# nrf52820 register map
Vendor: Nordic Semiconductor; Series: nrf52; File version: 1
CPU: CM4 r0p1, little endian, MPU, no FPU, 3 interrupt priority bits
Registers are 32-bit, read-write, reset 0x0 unless marked. A register's access mark holds for its fields unless they carry their own. Offsets are from the block's base; [hi:lo] are bit positions; {n}, {i} and the like mark numbered series; 'fields as' and 'values as' point back to an identical list.

## RTC0 — Real time counter 0
Base 0x4000B000
Same registers: RTC1 0x40011000
0x00 TASKS_START wo — Start RTC COUNTER
  [0] TASKS_START
    1=Trigger task
0x04 TASKS_STOP wo — Stop RTC COUNTER
  [0] TASKS_STOP
    1=Trigger task
0x08 TASKS_CLEAR wo — Clear RTC COUNTER
  [0] TASKS_CLEAR
    1=Trigger task
0x0C TASKS_TRIGOVRFLW wo — Set COUNTER to 0xFFFFF0
  [0] TASKS_TRIGOVRFLW
    1=Trigger task
0x100 EVENTS_TICK — Event on COUNTER increment
  [0] EVENTS_TICK
    0=NotGenerated (Event not generated); 1=Generated (Event generated)
0x104 EVENTS_OVRFLW — Event on COUNTER overflow
  [0] EVENTS_OVRFLW
    values as EVENTS_TICK.EVENTS_TICK
{0x140+4i} EVENTS_COMPARE[{i}] (i=0..3) — Description collection: Compare event on CC[n] match
  [0] EVENTS_COMPARE — Compare event on CC[n] match
    values as EVENTS_TICK.EVENTS_TICK
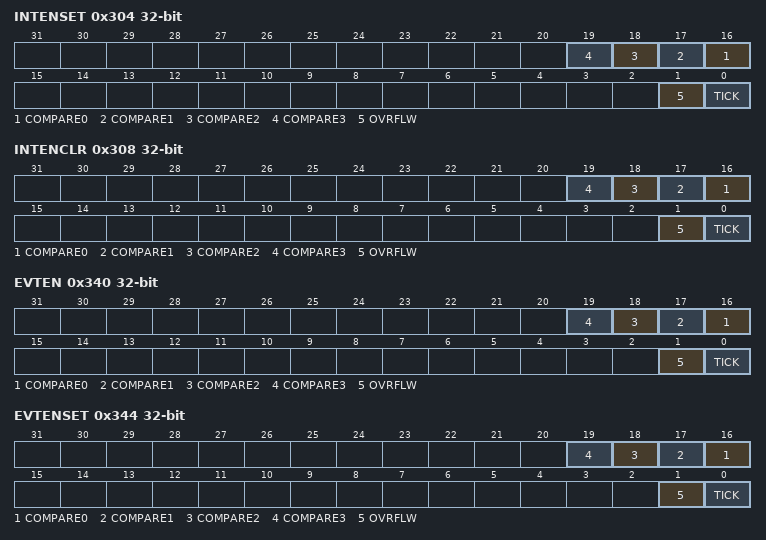
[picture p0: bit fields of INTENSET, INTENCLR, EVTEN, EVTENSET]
0x304 INTENSET — Enable interrupt
  [all] fields
    on read: 0=Disabled (Read: Disabled); 1=Enabled (Read: Enabled) | on write: 1=Set (Enable)
  [n+16] COMPARE{n} (n=0..3) — Write '1' to enable interrupt for event COMPARE[{n}]
  [1] OVRFLW — Write '1' to enable interrupt for event OVRFLW
  [0] TICK — Write '1' to enable interrupt for event TICK
0x308 INTENCLR — Disable interrupt
  [all] fields
    on read: 0=Disabled (Read: Disabled); 1=Enabled (Read: Enabled) | on write: 1=Clear (Disable)
  [n+16] COMPARE{n} (n=0..3) — Write '1' to disable interrupt for event COMPARE[{n}]
  [1] OVRFLW — Write '1' to disable interrupt for event OVRFLW
  [0] TICK — Write '1' to disable interrupt for event TICK
0x340 EVTEN — Enable or disable event routing
  [all] fields
    0=Disabled; 1=Enabled (Disable)
  [n+16] COMPARE{n} (n=0..3) — Enable or disable event routing for event COMPARE[{n}]
  [1] OVRFLW — Enable or disable event routing for event OVRFLW
  [0] TICK — Enable or disable event routing for event TICK
0x344 EVTENSET — Enable event routing
  [all] fields
    values as the fields of INTENSET
  [n+16] COMPARE{n} (n=0..3) — Write '1' to enable event routing for event COMPARE[{n}]
  [1] OVRFLW — Write '1' to enable event routing for event OVRFLW
  [0] TICK — Write '1' to enable event routing for event TICK
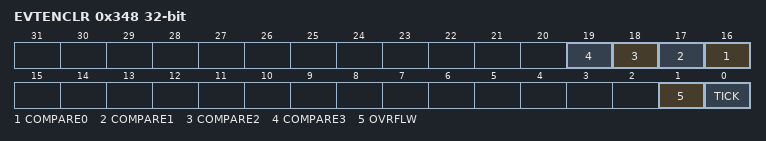
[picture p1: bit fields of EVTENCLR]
0x348 EVTENCLR — Disable event routing
  [all] fields
    values as the fields of INTENCLR
  [n+16] COMPARE{n} (n=0..3) — Write '1' to disable event routing for event COMPARE[{n}]
  [1] OVRFLW — Write '1' to disable event routing for event OVRFLW
  [0] TICK — Write '1' to disable event routing for event TICK
0x504 COUNTER ro — Current COUNTER value
  [23:0] COUNTER — Counter value
0x508 PRESCALER — 12 bit prescaler for COUNTER frequency (32768/(PRESCALER+1)). Must be written when RTC is stopped.
  [11:0] PRESCALER — Prescaler value
{0x540+4i} CC[{i}] (i=0..3) — Description collection: Compare register n
  [23:0] COMPARE — Compare value

## TEMP — Temperature Sensor
Base 0x4000C000
0x00 TASKS_START wo — Start temperature measurement
  [0] TASKS_START
    1=Trigger task
0x04 TASKS_STOP wo — Stop temperature measurement
  [0] TASKS_STOP
    1=Trigger task
0x100 EVENTS_DATARDY — Temperature measurement complete, data ready
  [0] EVENTS_DATARDY
    0=NotGenerated (Event not generated); 1=Generated (Event generated)
0x304 INTENSET — Enable interrupt
  [0] DATARDY — Write '1' to enable interrupt for event DATARDY
    on read: 0=Disabled (Read: Disabled); 1=Enabled (Read: Enabled) | on write: 1=Set (Enable)
0x308 INTENCLR — Disable interrupt
  [0] DATARDY — Write '1' to disable interrupt for event DATARDY
    on read: 0=Disabled (Read: Disabled); 1=Enabled (Read: Enabled) | on write: 1=Clear (Disable)
0x508 TEMP ro — Temperature in degC (0.25deg steps)
0x520 A0 reset 0x326 — Slope of first piecewise linear function
  [11:0] A0
0x524 A1 reset 0x348 — Slope of second piecewise linear function
  [11:0] A1
0x528 A2 reset 0x3AA — Slope of third piecewise linear function
  [11:0] A2
0x52C A3 reset 0x40E — Slope of fourth piecewise linear function
  [11:0] A3
0x530 A4 reset 0x4BD — Slope of fifth piecewise linear function
  [11:0] A4
0x534 A5 reset 0x5A3 — Slope of sixth piecewise linear function
  [11:0] A5
0x540 B0 reset 0x3FEF — y-intercept of first piecewise linear function
  [13:0] B0
0x544 B1 reset 0x3FBE — y-intercept of second piecewise linear function
  [13:0] B1
0x548 B2 reset 0x3FBE — y-intercept of third piecewise linear function
  [13:0] B2
0x54C B3 reset 0x12 — y-intercept of fourth piecewise linear function
  [13:0] B3
0x550 B4 reset 0x124 — y-intercept of fifth piecewise linear function
  [13:0] B4
0x554 B5 reset 0x27C — y-intercept of sixth piecewise linear function
  [13:0] B5
0x560 T0 reset 0xE2 — End point of first piecewise linear function
  [7:0] T0
0x564 T1 — End point of second piecewise linear function
  [7:0] T1
0x568 T2 reset 0x19 — End point of third piecewise linear function
  [7:0] T2
0x56C T3 reset 0x3C — End point of fourth piecewise linear function
  [7:0] T3
0x570 T4 reset 0x50 — End point of fifth piecewise linear function
  [7:0] T4
